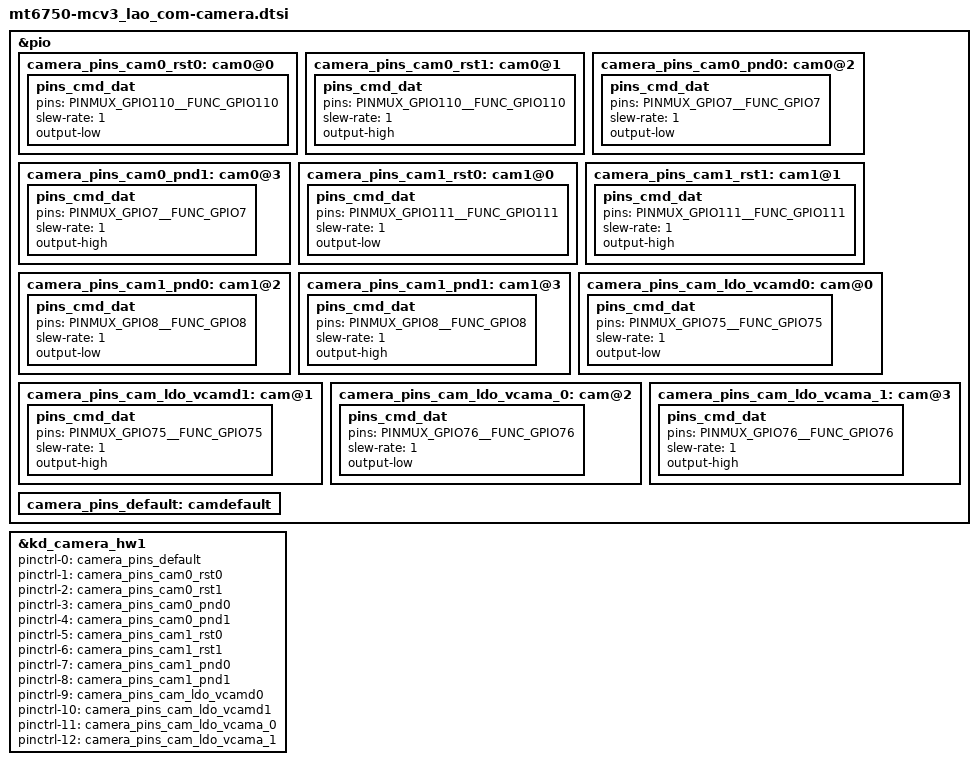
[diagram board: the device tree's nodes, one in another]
/*
 * LG Electronics CV3 camera device tree source
 *
 * Copyright (c) 2017 LG Electronics Co., Ltd.
 *              http://www.lge.com
 *
 */

/* CAMERA GPIO standardization */
&pio {
	camera_pins_cam0_rst0: cam0@0 {
	    pins_cmd_dat {
			pins = <PINMUX_GPIO110__FUNC_GPIO110>;
			slew-rate = <1>; /*direction 0:in, 1:out*/
			output-low;/*direction out used only. output_low or high*/
		};
	};
	camera_pins_cam0_rst1: cam0@1 {
	    pins_cmd_dat {
			pins = <PINMUX_GPIO110__FUNC_GPIO110>;
			slew-rate = <1>;
			output-high;
		};
	};
	camera_pins_cam0_pnd0: cam0@2 {
	    pins_cmd_dat {
			pins = <PINMUX_GPIO7__FUNC_GPIO7>;
			slew-rate = <1>;
			output-low;
		};
	};
	camera_pins_cam0_pnd1: cam0@3 {
	    pins_cmd_dat {
			pins = <PINMUX_GPIO7__FUNC_GPIO7>;
			slew-rate = <1>;
			output-high;
		};
	};

	camera_pins_cam1_rst0: cam1@0 {
	    pins_cmd_dat {
			pins = <PINMUX_GPIO111__FUNC_GPIO111>;
			slew-rate = <1>; /*direction 0:in, 1:out*/
			output-low;/*direction out used only. output_low or high*/
		};
	};
	camera_pins_cam1_rst1: cam1@1 {
	    pins_cmd_dat {
			pins = <PINMUX_GPIO111__FUNC_GPIO111>;
			slew-rate = <1>;
			output-high;
		};
	};
	camera_pins_cam1_pnd0: cam1@2 {
	    pins_cmd_dat {
			pins = <PINMUX_GPIO8__FUNC_GPIO8>;
			slew-rate = <1>;
			output-low;
		};
	};
	camera_pins_cam1_pnd1: cam1@3 {
	    pins_cmd_dat {
			pins = <PINMUX_GPIO8__FUNC_GPIO8>;
			slew-rate = <1>;
			output-high;
		};
	};
	camera_pins_cam_ldo_vcamd0: cam@0 {
		pins_cmd_dat {
			pins = <PINMUX_GPIO75__FUNC_GPIO75>;
			slew-rate = <1>;
			output-low;
		};
	};
	camera_pins_cam_ldo_vcamd1: cam@1 {
		pins_cmd_dat {
			pins = <PINMUX_GPIO75__FUNC_GPIO75>;
			slew-rate = <1>;
			output-high;
		};
	};
	camera_pins_cam_ldo_vcama_0: cam@2{
		pins_cmd_dat {
			pins = <PINMUX_GPIO76__FUNC_GPIO76>;
			slew-rate = <1>;
			output-low;
		};
	};
	camera_pins_cam_ldo_vcama_1: cam@3 {
		pins_cmd_dat {
			pins = <PINMUX_GPIO76__FUNC_GPIO76>;
			slew-rate = <1>;
			output-high;
		};
	};

	camera_pins_default: camdefault {
	};

};

&kd_camera_hw1 {
	pinctrl-names = "default",
			"cam0_rst0", "cam0_rst1", "cam0_pnd0", "cam0_pnd1",
			"cam1_rst0", "cam1_rst1", "cam1_pnd0", "cam1_pnd1",
			"cam_ldo_vcamd_0", "cam_ldo_vcamd_1",
			"cam_ldo_vcama_0", "cam_ldo_vcama_1";
	pinctrl-0 = <&camera_pins_default>;
	pinctrl-1 = <&camera_pins_cam0_rst0>;
	pinctrl-2 = <&camera_pins_cam0_rst1>;
	pinctrl-3 = <&camera_pins_cam0_pnd0>;
	pinctrl-4 = <&camera_pins_cam0_pnd1>;
	pinctrl-5 = <&camera_pins_cam1_rst0>;
	pinctrl-6 = <&camera_pins_cam1_rst1>;
	pinctrl-7 = <&camera_pins_cam1_pnd0>;
	pinctrl-8 = <&camera_pins_cam1_pnd1>;
		/* for ldo control by gpio */
	pinctrl-9 = <&camera_pins_cam_ldo_vcamd0>;
	pinctrl-10 = <&camera_pins_cam_ldo_vcamd1>;
	pinctrl-11 = <&camera_pins_cam_ldo_vcama_0>;
	pinctrl-12 = <&camera_pins_cam_ldo_vcama_1>;
	status = "okay";

};
/* CAMERA GPIO end */

